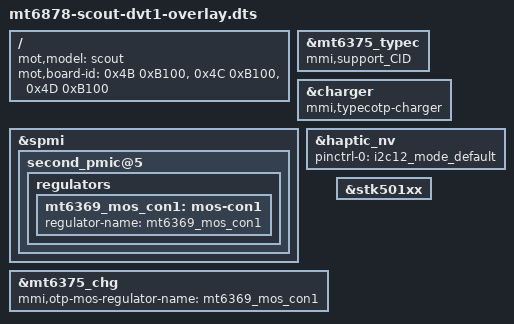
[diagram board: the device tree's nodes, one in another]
/* Copyright (c) 2023, Motorola Mobility Inc. All rights reserved.
 *
 * This program is free software; you can redistribute it and/or modify
 * it under the terms of the GNU General Public License version 2 and
 * only version 2 as published by the Free Software Foundation.
 *
 * This program is distributed in the hope that it will be useful,
 * but WITHOUT ANY WARRANTY; without even the implied warranty of
 * MERCHANTABILITY or FITNESS FOR A PARTICULAR PURPOSE.  See the
 * GNU General Public License for more details.
 */

/dts-v1/;
/plugin/;

#include "mediatek/mt6878-scout-common-overlay.dtsi"

/* Board match root node */
/ {
	fragment@model {
		target-path = "/";
		__overlay__ {
			mot,model = "scout";
			mot,board-id = <0x4B 0xB100>, <0x4C 0xB100>, <0x4D 0xB100>;
		};
	};
};

&mt6375_typec {
	mmi,support_CID;
};

&charger {
	/*typec_otp*/
	mmi,typecotp-charger;
};

&spmi {
	second_pmic@5 {
		regulators {
			mt6369_mos_con1: mos-con1 {
				regulator-name = "mt6369_mos_con1";
			};
		};
	};
};

&haptic_nv {
		pinctrl-names = "default";
		pinctrl-0 = <&i2c12_mode_default>;
};

&mt6375_chg {
	mmi,otp-mos-regulator-name = "mt6369_mos_con1";
};

&stk501xx {
	status = "okay";
};

#include <scout_evb/cust.dtsi>
/*End of this file, DO NOT ADD ANYTHING HERE*/
